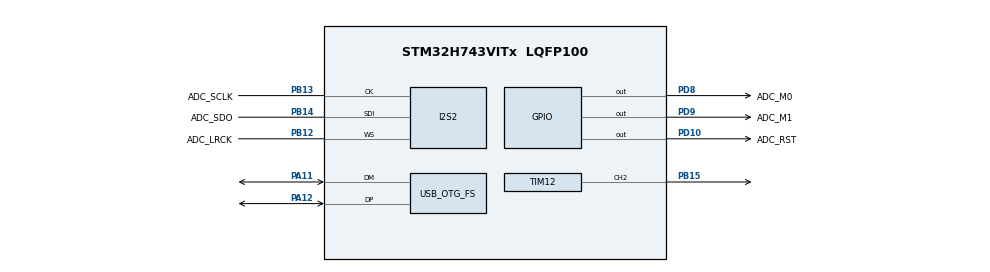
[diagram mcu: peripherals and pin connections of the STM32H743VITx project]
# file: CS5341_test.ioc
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I2S2.AudioFreq=I2S_AUDIOFREQ_192K
I2S2.DataFormat=I2S_DATAFORMAT_24B
I2S2.ErrorAudioFreq=1.72 %
I2S2.Instance=SPI$Index
I2S2.RealAudioFreq=195.312 KHz
I2S2.Standard=I2S_STANDARD_MSB
I2S2.WSInversion=I2S_WS_INVERSION_ENABLE
Mcu.Family=STM32H7
Mcu.Name=STM32H743VITx
Mcu.Package=LQFP100
NVIC.OTG_FS_IRQn=true\:0\:0\:false\:false\:true\:false\:true
NVIC.PriorityGroup=NVIC_PRIORITYGROUP_4
PA11.Mode=Device_Only
PA11.Signal=USB_OTG_FS_DM
PA12.Mode=Device_Only
PA12.Signal=USB_OTG_FS_DP
PB12.GPIO_Label=ADC_LRCK
PB12.GPIO_Speed=GPIO_SPEED_FREQ_VERY_HIGH
PB12.Mode=Half_Duplex_Master_Rx
PB12.Signal=I2S2_WS
PB13.GPIO_Label=ADC_SCLK
PB13.GPIO_Speed=GPIO_SPEED_FREQ_VERY_HIGH
PB13.Mode=Half_Duplex_Master_Rx
PB13.Signal=I2S2_CK
PB14.GPIO_Label=ADC_SDO
PB14.GPIO_PuPd=GPIO_PULLDOWN
PB14.GPIO_Speed=GPIO_SPEED_FREQ_VERY_HIGH
PB14.Mode=Half_Duplex_Master_Rx
PB14.Signal=I2S2_SDI
PB15.Signal=S_TIM12_CH2
PD10.GPIO_Label=ADC_RST
PD10.GPIO_Speed=GPIO_SPEED_FREQ_VERY_HIGH
PD10.PinState=GPIO_PIN_RESET
PD10.Signal=GPIO_Output
PD8.GPIO_Label=ADC_M0
PD8.GPIO_Speed=GPIO_SPEED_FREQ_VERY_HIGH
PD8.PinState=GPIO_PIN_SET
PD8.Signal=GPIO_Output
PD9.GPIO_Label=ADC_M1
PD9.GPIO_Speed=GPIO_SPEED_FREQ_VERY_HIGH
PD9.PinState=GPIO_PIN_SET
PD9.Signal=GPIO_Output
PH0-OSC_IN\ (PH0).Mode=HSE-External-Oscillator
PH0-OSC_IN\ (PH0).Signal=RCC_OSC_IN
PH1-OSC_OUT\ (PH1).Mode=HSE-External-Oscillator
PH1-OSC_OUT\ (PH1).Signal=RCC_OSC_OUT
ProjectManager.HeapSize=0x200
ProjectManager.StackSize=0x400
ProjectManager.TargetToolchain=STM32CubeIDE
RCC.ADCFreq_Value=100000000
RCC.APB1Freq_Value=100000000
RCC.APB2Freq_Value=100000000
RCC.APB3Freq_Value=100000000
RCC.APB4Freq_Value=100000000
RCC.CortexFreq_Value=400000000
RCC.D1PPRE=RCC_APB3_DIV2
RCC.D2PPRE1=RCC_APB1_DIV2
RCC.D2PPRE2=RCC_APB2_DIV2
RCC.D3PPRE=RCC_APB4_DIV2
RCC.DIVM1=2
RCC.DIVM2=2
RCC.DIVM3=2
RCC.DIVN1=64
RCC.DIVN2=16
RCC.DIVN3=16
RCC.DIVQ1=8
RCC.HCLKFreq_Value=200000000
RCC.HPRE=RCC_HCLK_DIV2
RCC.PLLSourceVirtual=RCC_PLLSOURCE_HSE
RCC.SYSCLKFreq_VALUE=400000000
RCC.SYSCLKSource=RCC_SYSCLKSOURCE_PLLCLK
RCC.USBCLockSelection=RCC_USBCLKSOURCE_HSI48
RCC.USBFreq_Value=48000000
SH.S_TIM12_CH2.0=TIM12_CH2,PWM Generation2 CH2
TIM12.Channel-PWM\ Generation2\ CH2=TIM_CHANNEL_2
TIM12.Period=7
TIM12.Pulse-PWM\ Generation2\ CH2=3
USB_DEVICE.CLASS_NAME_FS=CDC
USB_DEVICE.VirtualMode-CDC_FS=Cdc
USB_DEVICE.VirtualModeFS=Cdc_FS
USB_OTG_FS.VirtualMode=Device_Only
VP_TIM12_VS_ClockSourceINT.Mode=Internal
VP_USB_DEVICE_VS_USB_DEVICE_CDC_FS.Mode=CDC_FS
board=custom

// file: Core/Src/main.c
/* USER CODE BEGIN Header */
/**
  ******************************************************************************
  * @file           : main.c
  * @brief          : Main program body
  ******************************************************************************
  * @attention
  *
  * <h2><center>&copy; Copyright (c) 2021 STMicroelectronics.
  * All rights reserved.</center></h2>
  *
  * This software component is licensed by ST under BSD 3-Clause license,
  * the "License"; You may not use this file except in compliance with the
  * License. You may obtain a copy of the License at:
  *                        opensource.org/licenses/BSD-3-Clause
  *
  ******************************************************************************
  */
/* USER CODE END Header */
#include "main.h"
#include "usb_device.h"

I2S_HandleTypeDef hi2s2;

TIM_HandleTypeDef htim12;

/* USER CODE BEGIN PV */

uint32_t i2s_adc_buffer[2];

/* USER CODE END PV */

void SystemClock_Config(void);
static void MX_GPIO_Init(void);
static void MX_I2S2_Init(void);
static void MX_TIM12_Init(void);

int main(void)
{

  /* MCU Configuration--------------------------------------------------------*/

  /* Reset of all peripherals, Initializes the Flash interface and the Systick. */
  HAL_Init();

  /* Configure the system clock */
  SystemClock_Config();

  /* Initialize all configured peripherals */
  MX_GPIO_Init();
  MX_I2S2_Init();
  MX_TIM12_Init();
  MX_USB_DEVICE_Init();
  /* USER CODE BEGIN 2 */

  HAL_TIM_PWM_Init(&htim12);
  HAL_I2S_Init(&hi2s2);

  HAL_TIM_PWM_Start(&htim12, TIM_CHANNEL_2);
  HAL_Delay(100);
  HAL_GPIO_WritePin (GPIOD, GPIO_PIN_10, GPIO_PIN_SET);

  /* USER CODE END 2 */

  /* Infinite loop */
  while (1)
  {
	  HAL_I2S_Receive(&hi2s2, (uint16_t*)i2s_adc_buffer, 2, HAL_MAX_DELAY);
	  int32_t adc_input[2];
	  if (i2s_adc_buffer[0] >= 0x00800000) adc_input[0] = i2s_adc_buffer[0] - (int32_t)0x00FFFFFF; else adc_input[0] = (int32_t)i2s_adc_buffer[0];
	  if (i2s_adc_buffer[1] >= 0x00800000) adc_input[1] = i2s_adc_buffer[1] - (int32_t)0x00FFFFFF; else adc_input[1] = (int32_t)i2s_adc_buffer[1];

	  char buf[100];
	  sprintf(buf,"%d,%d\r\n", adc_input[0], adc_input[1]);
	  CDC_Transmit_FS(buf, strlen(buf));
	  HAL_Delay(1);

  }
}

void SystemClock_Config(void)
{
  RCC_OscInitTypeDef RCC_OscInitStruct = {0};
  RCC_ClkInitTypeDef RCC_ClkInitStruct = {0};

  /** Supply configuration update enable
  */
  HAL_PWREx_ConfigSupply(PWR_LDO_SUPPLY);
  /** Configure the main internal regulator output voltage
  */
  __HAL_PWR_VOLTAGESCALING_CONFIG(PWR_REGULATOR_VOLTAGE_SCALE1);

  while(!__HAL_PWR_GET_FLAG(PWR_FLAG_VOSRDY)) {}
  /** Initializes the RCC Oscillators according to the specified parameters
  * in the RCC_OscInitTypeDef structure.
  */
  RCC_OscInitStruct.OscillatorType = RCC_OSCILLATORTYPE_HSI48|RCC_OSCILLATORTYPE_HSE;
  RCC_OscInitStruct.HSEState = RCC_HSE_ON;
  RCC_OscInitStruct.HSI48State = RCC_HSI48_ON;
  RCC_OscInitStruct.PLL.PLLState = RCC_PLL_ON;
  RCC_OscInitStruct.PLL.PLLSource = RCC_PLLSOURCE_HSE;
  RCC_OscInitStruct.PLL.PLLM = 2;
  RCC_OscInitStruct.PLL.PLLN = 64;
  RCC_OscInitStruct.PLL.PLLP = 2;
  RCC_OscInitStruct.PLL.PLLQ = 8;
  RCC_OscInitStruct.PLL.PLLR = 2;
  RCC_OscInitStruct.PLL.PLLRGE = RCC_PLL1VCIRANGE_3;
  RCC_OscInitStruct.PLL.PLLVCOSEL = RCC_PLL1VCOWIDE;
  RCC_OscInitStruct.PLL.PLLFRACN = 0;
  if (HAL_RCC_OscConfig(&RCC_OscInitStruct) != HAL_OK)
  {
    Error_Handler();
  }
  /** Initializes the CPU, AHB and APB buses clocks
  */
  RCC_ClkInitStruct.ClockType = RCC_CLOCKTYPE_HCLK|RCC_CLOCKTYPE_SYSCLK
                              |RCC_CLOCKTYPE_PCLK1|RCC_CLOCKTYPE_PCLK2
                              |RCC_CLOCKTYPE_D3PCLK1|RCC_CLOCKTYPE_D1PCLK1;
  RCC_ClkInitStruct.SYSCLKSource = RCC_SYSCLKSOURCE_PLLCLK;
  RCC_ClkInitStruct.SYSCLKDivider = RCC_SYSCLK_DIV1;
  RCC_ClkInitStruct.AHBCLKDivider = RCC_HCLK_DIV2;
  RCC_ClkInitStruct.APB3CLKDivider = RCC_APB3_DIV2;
  RCC_ClkInitStruct.APB1CLKDivider = RCC_APB1_DIV2;
  RCC_ClkInitStruct.APB2CLKDivider = RCC_APB2_DIV2;
  RCC_ClkInitStruct.APB4CLKDivider = RCC_APB4_DIV2;

  if (HAL_RCC_ClockConfig(&RCC_ClkInitStruct, FLASH_LATENCY_2) != HAL_OK)
  {
    Error_Handler();
  }
}

static void MX_I2S2_Init(void)
{

  hi2s2.Instance = SPI2;
  hi2s2.Init.Mode = I2S_MODE_MASTER_RX;
  hi2s2.Init.Standard = I2S_STANDARD_MSB;
  hi2s2.Init.DataFormat = I2S_DATAFORMAT_24B;
  hi2s2.Init.MCLKOutput = I2S_MCLKOUTPUT_DISABLE;
  hi2s2.Init.AudioFreq = I2S_AUDIOFREQ_192K;
  hi2s2.Init.CPOL = I2S_CPOL_LOW;
  hi2s2.Init.FirstBit = I2S_FIRSTBIT_MSB;
  hi2s2.Init.WSInversion = I2S_WS_INVERSION_ENABLE;
  hi2s2.Init.Data24BitAlignment = I2S_DATA_24BIT_ALIGNMENT_RIGHT;
  hi2s2.Init.MasterKeepIOState = I2S_MASTER_KEEP_IO_STATE_DISABLE;
  if (HAL_I2S_Init(&hi2s2) != HAL_OK)
  {
    Error_Handler();
  }

}

static void MX_TIM12_Init(void)
{

  TIM_ClockConfigTypeDef sClockSourceConfig = {0};
  TIM_OC_InitTypeDef sConfigOC = {0};

  htim12.Instance = TIM12;
  htim12.Init.Prescaler = 0;
  htim12.Init.CounterMode = TIM_COUNTERMODE_UP;
  htim12.Init.Period = 7;
  htim12.Init.ClockDivision = TIM_CLOCKDIVISION_DIV1;
  htim12.Init.AutoReloadPreload = TIM_AUTORELOAD_PRELOAD_DISABLE;
  if (HAL_TIM_Base_Init(&htim12) != HAL_OK)
  {
    Error_Handler();
  }
  sClockSourceConfig.ClockSource = TIM_CLOCKSOURCE_INTERNAL;
  if (HAL_TIM_ConfigClockSource(&htim12, &sClockSourceConfig) != HAL_OK)
  {
    Error_Handler();
  }
  if (HAL_TIM_PWM_Init(&htim12) != HAL_OK)
  {
    Error_Handler();
  }
  sConfigOC.OCMode = TIM_OCMODE_PWM1;
  sConfigOC.Pulse = 3;
  sConfigOC.OCPolarity = TIM_OCPOLARITY_HIGH;
  sConfigOC.OCFastMode = TIM_OCFAST_DISABLE;
  if (HAL_TIM_PWM_ConfigChannel(&htim12, &sConfigOC, TIM_CHANNEL_2) != HAL_OK)
  {
    Error_Handler();
  }
  HAL_TIM_MspPostInit(&htim12);

}

static void MX_GPIO_Init(void)
{
  GPIO_InitTypeDef GPIO_InitStruct = {0};

  /* GPIO Ports Clock Enable */
  __HAL_RCC_GPIOE_CLK_ENABLE();
  __HAL_RCC_GPIOC_CLK_ENABLE();
  __HAL_RCC_GPIOH_CLK_ENABLE();
  __HAL_RCC_GPIOA_CLK_ENABLE();
  __HAL_RCC_GPIOB_CLK_ENABLE();
  __HAL_RCC_GPIOD_CLK_ENABLE();

  /*Configure GPIO pin Output Level */
  HAL_GPIO_WritePin(GPIOD, ADC_M0_Pin|ADC_M1_Pin, GPIO_PIN_SET);

  /*Configure GPIO pin Output Level */
  HAL_GPIO_WritePin(ADC_RST_GPIO_Port, ADC_RST_Pin, GPIO_PIN_RESET);

  /*Configure GPIO pins : PE2 PE3 PE4 PE5
                           PE6 PE7 PE8 PE9
                           PE10 PE11 PE12 PE13
                           PE14 PE15 PE0 PE1 */
  GPIO_InitStruct.Pin = GPIO_PIN_2|GPIO_PIN_3|GPIO_PIN_4|GPIO_PIN_5
                          |GPIO_PIN_6|GPIO_PIN_7|GPIO_PIN_8|GPIO_PIN_9
                          |GPIO_PIN_10|GPIO_PIN_11|GPIO_PIN_12|GPIO_PIN_13
                          |GPIO_PIN_14|GPIO_PIN_15|GPIO_PIN_0|GPIO_PIN_1;
  GPIO_InitStruct.Mode = GPIO_MODE_ANALOG;
  GPIO_InitStruct.Pull = GPIO_NOPULL;
  HAL_GPIO_Init(GPIOE, &GPIO_InitStruct);

  /*Configure GPIO pins : PC13 PC14 PC15 PC0
                           PC1 PC2 PC3 PC4
                           PC5 PC6 PC7 PC8
                           PC9 PC10 PC11 PC12 */
  GPIO_InitStruct.Pin = GPIO_PIN_13|GPIO_PIN_14|GPIO_PIN_15|GPIO_PIN_0
                          |GPIO_PIN_1|GPIO_PIN_2|GPIO_PIN_3|GPIO_PIN_4
                          |GPIO_PIN_5|GPIO_PIN_6|GPIO_PIN_7|GPIO_PIN_8
                          |GPIO_PIN_9|GPIO_PIN_10|GPIO_PIN_11|GPIO_PIN_12;
  GPIO_InitStruct.Mode = GPIO_MODE_ANALOG;
  GPIO_InitStruct.Pull = GPIO_NOPULL;
  HAL_GPIO_Init(GPIOC, &GPIO_InitStruct);

  /*Configure GPIO pins : PA0 PA1 PA2 PA3
                           PA4 PA5 PA6 PA7
                           PA8 PA9 PA10 PA13
                           PA14 PA15 */
  GPIO_InitStruct.Pin = GPIO_PIN_0|GPIO_PIN_1|GPIO_PIN_2|GPIO_PIN_3
                          |GPIO_PIN_4|GPIO_PIN_5|GPIO_PIN_6|GPIO_PIN_7
                          |GPIO_PIN_8|GPIO_PIN_9|GPIO_PIN_10|GPIO_PIN_13
                          |GPIO_PIN_14|GPIO_PIN_15;
  GPIO_InitStruct.Mode = GPIO_MODE_ANALOG;
  GPIO_InitStruct.Pull = GPIO_NOPULL;
  HAL_GPIO_Init(GPIOA, &GPIO_InitStruct);

  /*Configure GPIO pins : PB0 PB1 PB2 PB10
                           PB11 PB3 PB4 PB5
                           PB6 PB7 PB8 PB9 */
  GPIO_InitStruct.Pin = GPIO_PIN_0|GPIO_PIN_1|GPIO_PIN_2|GPIO_PIN_10
                          |GPIO_PIN_11|GPIO_PIN_3|GPIO_PIN_4|GPIO_PIN_5
                          |GPIO_PIN_6|GPIO_PIN_7|GPIO_PIN_8|GPIO_PIN_9;
  GPIO_InitStruct.Mode = GPIO_MODE_ANALOG;
  GPIO_InitStruct.Pull = GPIO_NOPULL;
  HAL_GPIO_Init(GPIOB, &GPIO_InitStruct);

  /*Configure GPIO pins : ADC_M0_Pin ADC_M1_Pin ADC_RST_Pin */
  GPIO_InitStruct.Pin = ADC_M0_Pin|ADC_M1_Pin|ADC_RST_Pin;
  GPIO_InitStruct.Mode = GPIO_MODE_OUTPUT_PP;
  GPIO_InitStruct.Pull = GPIO_NOPULL;
  GPIO_InitStruct.Speed = GPIO_SPEED_FREQ_VERY_HIGH;
  HAL_GPIO_Init(GPIOD, &GPIO_InitStruct);

  /*Configure GPIO pins : PD11 PD12 PD13 PD14
                           PD15 PD0 PD1 PD2
                           PD3 PD4 PD5 PD6
                           PD7 */
  GPIO_InitStruct.Pin = GPIO_PIN_11|GPIO_PIN_12|GPIO_PIN_13|GPIO_PIN_14
                          |GPIO_PIN_15|GPIO_PIN_0|GPIO_PIN_1|GPIO_PIN_2
                          |GPIO_PIN_3|GPIO_PIN_4|GPIO_PIN_5|GPIO_PIN_6
                          |GPIO_PIN_7;
  GPIO_InitStruct.Mode = GPIO_MODE_ANALOG;
  GPIO_InitStruct.Pull = GPIO_NOPULL;
  HAL_GPIO_Init(GPIOD, &GPIO_InitStruct);

}

void Error_Handler(void)
{
  __disable_irq();
  while (1)
  {
  }
}

/************************ (C) COPYRIGHT STMicroelectronics *****END OF FILE****/
